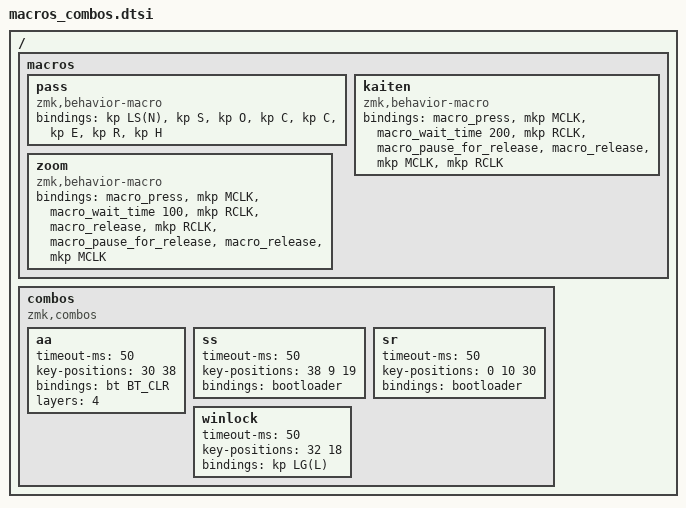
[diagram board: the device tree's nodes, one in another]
#include <behaviors.dtsi>
#include <dt-bindings/zmk/keys.h>

// Generated by ZMK Studio Skinner
// マクロ・コンボ定義 — このファイルを .keymap で #include してください
// 2026-05-26T14:22:15.842Z

/ {
    macros {
        pass: pass {
            compatible = "zmk,behavior-macro";
            #binding-cells = <0>;
            bindings = <&kp LS(N) &kp S &kp O &kp C &kp C &kp E &kp R &kp H>;
        };
        kaiten: kaiten {
            compatible = "zmk,behavior-macro";
            #binding-cells = <0>;
            bindings = <&macro_press>, <&mkp MCLK>, <&macro_wait_time 200>, <&mkp RCLK>, <&macro_pause_for_release>, <&macro_release>, <&mkp MCLK &mkp RCLK>;
        };
        zoom: zoom {
            compatible = "zmk,behavior-macro";
            #binding-cells = <0>;
            bindings = <&macro_press>, <&mkp MCLK>, <&macro_wait_time 100>, <&mkp RCLK>, <&macro_release>, <&mkp RCLK>, <&macro_pause_for_release>, <&macro_release>, <&mkp MCLK>;
        };
    };

    combos {
        compatible = "zmk,combos";

        aa {
            timeout-ms = <50>;
            key-positions = <30 38>;
            bindings = <&bt BT_CLR>;
            layers = <4>;
        };
        ss {
            timeout-ms = <50>;
            key-positions = <38 9 19>;
            bindings = <&bootloader>;
        };
        sr {
            timeout-ms = <50>;
            key-positions = <0 10 30>;
            bindings = <&bootloader>;
        };
        winlock {
            timeout-ms = <50>;
            key-positions = <32 18>;
            bindings = <&kp LG(L)>;
        };
    };
};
